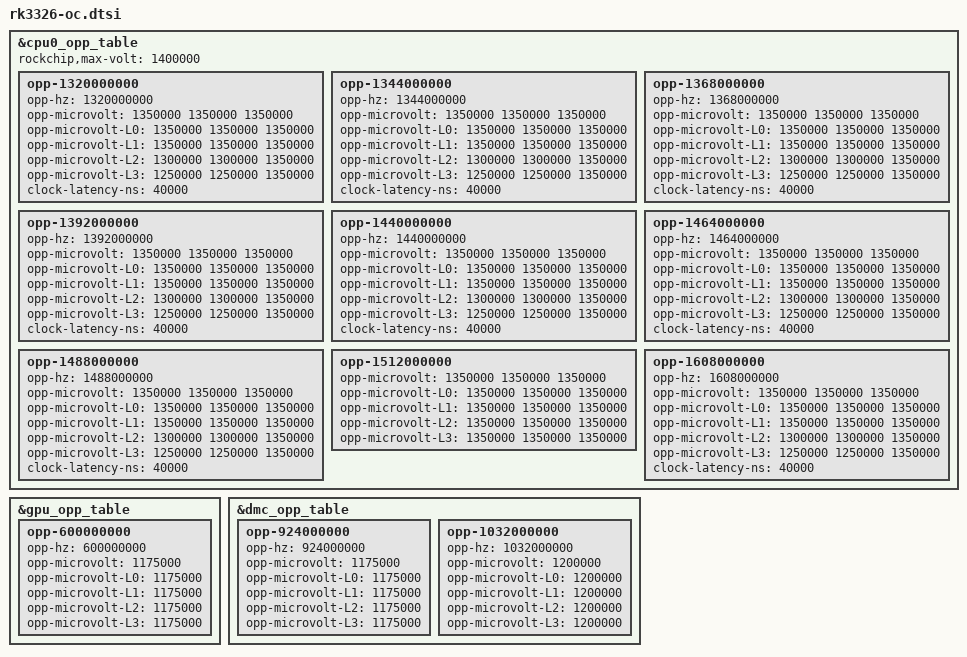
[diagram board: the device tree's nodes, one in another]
// SPDX-License-Identifier: (GPL-2.0+ OR MIT)
/*
 * R36S clone overclock OPPs, based on the 4.4 rk3326-oc.dtsi.
 * Include from the selected board DTS only.
 *
 * The 5.10 clock and DDR firmware expose 600 MHz GPU and 1032 MHz DMC.
 * The 4.4 640/1040 MHz requests resolve to these physical rates, so do not
 * add duplicate nominal OPPs.
 */

&cpu0_opp_table {
	rockchip,max-volt = <1400000>;

	/* Complete the supported 24 MHz CPU PLL steps. */
	opp-1320000000 {
		opp-hz = /bits/ 64 <1320000000>;
		opp-microvolt = <1350000 1350000 1350000>;
		opp-microvolt-L0 = <1350000 1350000 1350000>;
		opp-microvolt-L1 = <1350000 1350000 1350000>;
		opp-microvolt-L2 = <1300000 1300000 1350000>;
		opp-microvolt-L3 = <1250000 1250000 1350000>;
		clock-latency-ns = <40000>;
	};
	opp-1344000000 {
		opp-hz = /bits/ 64 <1344000000>;
		opp-microvolt = <1350000 1350000 1350000>;
		opp-microvolt-L0 = <1350000 1350000 1350000>;
		opp-microvolt-L1 = <1350000 1350000 1350000>;
		opp-microvolt-L2 = <1300000 1300000 1350000>;
		opp-microvolt-L3 = <1250000 1250000 1350000>;
		clock-latency-ns = <40000>;
	};
	opp-1368000000 {
		opp-hz = /bits/ 64 <1368000000>;
		opp-microvolt = <1350000 1350000 1350000>;
		opp-microvolt-L0 = <1350000 1350000 1350000>;
		opp-microvolt-L1 = <1350000 1350000 1350000>;
		opp-microvolt-L2 = <1300000 1300000 1350000>;
		opp-microvolt-L3 = <1250000 1250000 1350000>;
		clock-latency-ns = <40000>;
	};
	opp-1392000000 {
		opp-hz = /bits/ 64 <1392000000>;
		opp-microvolt = <1350000 1350000 1350000>;
		opp-microvolt-L0 = <1350000 1350000 1350000>;
		opp-microvolt-L1 = <1350000 1350000 1350000>;
		opp-microvolt-L2 = <1300000 1300000 1350000>;
		opp-microvolt-L3 = <1250000 1250000 1350000>;
		clock-latency-ns = <40000>;
	};
	opp-1440000000 {
		opp-hz = /bits/ 64 <1440000000>;
		opp-microvolt = <1350000 1350000 1350000>;
		opp-microvolt-L0 = <1350000 1350000 1350000>;
		opp-microvolt-L1 = <1350000 1350000 1350000>;
		opp-microvolt-L2 = <1300000 1300000 1350000>;
		opp-microvolt-L3 = <1250000 1250000 1350000>;
		clock-latency-ns = <40000>;
	};
	opp-1464000000 {
		opp-hz = /bits/ 64 <1464000000>;
		opp-microvolt = <1350000 1350000 1350000>;
		opp-microvolt-L0 = <1350000 1350000 1350000>;
		opp-microvolt-L1 = <1350000 1350000 1350000>;
		opp-microvolt-L2 = <1300000 1300000 1350000>;
		opp-microvolt-L3 = <1250000 1250000 1350000>;
		clock-latency-ns = <40000>;
	};
	opp-1488000000 {
		opp-hz = /bits/ 64 <1488000000>;
		opp-microvolt = <1350000 1350000 1350000>;
		opp-microvolt-L0 = <1350000 1350000 1350000>;
		opp-microvolt-L1 = <1350000 1350000 1350000>;
		opp-microvolt-L2 = <1300000 1300000 1350000>;
		opp-microvolt-L3 = <1250000 1250000 1350000>;
		clock-latency-ns = <40000>;
	};
	/* This device passed a four-core 1.512 GHz run at 1.35 V. */
	opp-1512000000 {
		opp-microvolt = <1350000 1350000 1350000>;
		opp-microvolt-L0 = <1350000 1350000 1350000>;
		opp-microvolt-L1 = <1350000 1350000 1350000>;
		opp-microvolt-L2 = <1350000 1350000 1350000>;
		opp-microvolt-L3 = <1350000 1350000 1350000>;
	};
	opp-1608000000 {
		opp-hz = /bits/ 64 <1608000000>;
		opp-microvolt = <1350000 1350000 1350000>;
		opp-microvolt-L0 = <1350000 1350000 1350000>;
		opp-microvolt-L1 = <1350000 1350000 1350000>;
		opp-microvolt-L2 = <1300000 1300000 1350000>;
		opp-microvolt-L3 = <1250000 1250000 1350000>;
		clock-latency-ns = <40000>;
	};
};

&gpu_opp_table {
	opp-600000000 {
		opp-hz = /bits/ 64 <600000000>;
		opp-microvolt = <1175000>;
		opp-microvolt-L0 = <1175000>;
		opp-microvolt-L1 = <1175000>;
		opp-microvolt-L2 = <1175000>;
		opp-microvolt-L3 = <1175000>;
	};
};

&dmc_opp_table {
	opp-924000000 {
		opp-hz = /bits/ 64 <924000000>;
		opp-microvolt = <1175000>;
		opp-microvolt-L0 = <1175000>;
		opp-microvolt-L1 = <1175000>;
		opp-microvolt-L2 = <1175000>;
		opp-microvolt-L3 = <1175000>;
	};
	/* Trusted firmware realizes the 4.4 tree's 1040 MHz request as 1032 MHz. */
	opp-1032000000 {
		opp-hz = /bits/ 64 <1032000000>;
		opp-microvolt = <1200000>;
		opp-microvolt-L0 = <1200000>;
		opp-microvolt-L1 = <1200000>;
		opp-microvolt-L2 = <1200000>;
		opp-microvolt-L3 = <1200000>;
	};
};
